# STM32H743 register map
File version: 2.4
CPU: CM7 r0p1, little endian, MPU, FPU, 4 interrupt priority bits
Registers are 32-bit, read-write, reset 0x0 unless marked. A register's access mark holds for its fields unless they carry their own. Offsets are from the block's base; [hi:lo] are bit positions; {n}, {i} and the like mark numbered series; 'fields as' and 'values as' point back to an identical list.

## RAMECC2 — ECC 控制器与各 RAM 区域相关联
Base 0x48023000
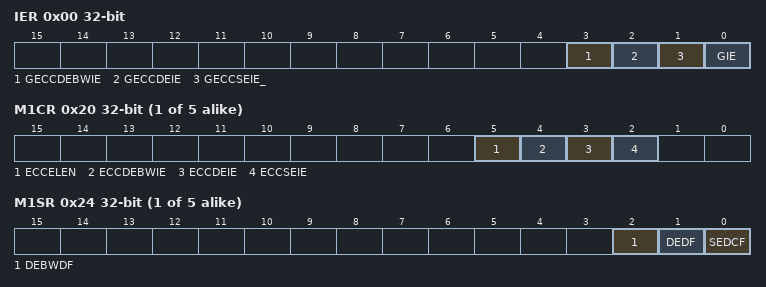
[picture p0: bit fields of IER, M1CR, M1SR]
0x00 IER — RAMECC 中断使能寄存器
  [3] GECCDEBWIE — 全局 ECC 字节写入（BW）双错误中断使能
  [2] GECCDEIE — 全局 ECC 双错误中断使能
  [1] GECCSEIE_ — 全局 ECC 单错误中断使能
  [0] GIE — 全局中断使能
{0x0+0x20*i} M{i}CR (i=1..5) — RAMECC 监视器 x 配置寄存器
  [5] ECCELEN — ECC 错误锁存使能
  [4] ECCDEBWIE — ECC 字节写入（BW）双错误中断使能
  [3] ECCDEIE — ECC 双错误中断使能
  [2] ECCSEIE — ECC 单错误中断使能
{0x4+0x20*i} M{i}SR (i=1..5) — RAMECC 监视器 x 状态寄存器
  [2] DEBWDF — ECC 字节写入（BW）双错误检测标志
  [1] DEDF — ECC 双错误检测标志
  [0] SEDCF — ECC 单错误检测并纠正标志
{0x8+0x20*i} M{i}FAR ro (i=1..4) — RAMECC 监视器 x 故障地址寄存器
  [31:0] FADD — ECC 错误故障地址
{0xC+0x20*i} M{i}FDRL ro (i=1..5) — RAMECC 监视器 x 故障数据低字寄存器
  [31:0] FDATAL — 故障数据低字
0x30 M1FDRH ro — RAMECC 监视器 x 故障数据高字寄存器
  [31:0] FDATAH — 故障数据高字（64 位存储器）
0x34 M1FECR — RAMECC 监视器 x 故障 ECC 错误码寄存器
  [31:0] FEC — 故障错误码
0x50 M2FDRH — RAMECC 监视器 x 故障数据高字寄存器
  [31:0] FDATAH — 故障数据高字（64 位存储器）
0x58 M2FECR — RAMECC 监视器 x 故障 ECC 错误码寄存器
  [31:0] FEC — 故障错误码
0x70 M3FDRH ro — RAMECC 监视器 x 故障数据高字寄存器
  [31:0] FDATAH — 故障数据高字（64 位存储器）
0x7C M3FECR ro — RAMECC 监视器 x 故障 ECC 错误码寄存器
  [31:0] FEC — 故障错误码
0x90 M4FDRH ro — RAMECC 监视器 x 故障数据高字寄存器
  [31:0] FDATAH — 故障数据高字（64 位存储器）
0x90 M4FECR ro (alternate view of M4FDRH) — RAMECC 监视器 x 故障 ECC 错误码寄存器
  [31:0] FEC — 故障错误码
0xA8 M5FAR — RAMECC 监视器 x 故障地址寄存器
  [31:0] FADD — ECC 错误故障地址
0xB0 M5FDRH ro — RAMECC 监视器 x 故障数据高字寄存器
  [31:0] FEC — 故障错误码
0xB4 M5FECR ro — RAMECC 监视器 x 故障 ECC 错误码寄存器
  [31:0] FEC — 故障错误码

## RAMECC3 — ECC 控制器与各 RAM 区域相关联
Base 0x58027000
Registers as RAMECC2, without M{n}CR (n=3..5), M{n}SR (n=3..5), M{n}FAR (n=3..5), M{n}FDRL (n=3..5), M{n}FDRH (n=3..5), M{n}FECR (n=3..5).

## DELAY_Block_SDMMC1 — SDMMC1 延时模块
Base 0x52008000
Same registers: DELAY_Block_SDMMC2 0x48022800, DELAY_Block_QUADSPI 0x52006000
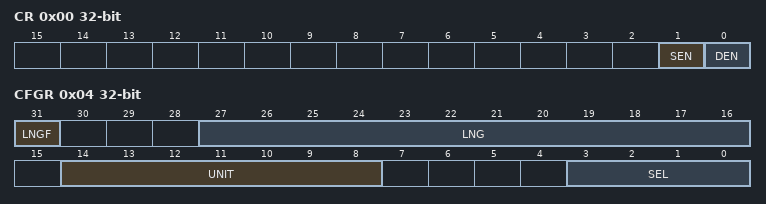
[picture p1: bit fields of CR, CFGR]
0x00 CR — DLYB 控制寄存器
  [1] SEN — 采样长度使能位
  [0] DEN — 延时模块使能位
0x04 CFGR — DLYB 配置寄存器
  [31] LNGF — 长度有效标志
  [27:16] LNG — 延时线长度值
  [14:8] UNIT — 定义单位延时单元的延时量
  [3:0] SEL — 选择输出时钟的相位

## AXI — AXI 互连寄存器
Base 0x51000000
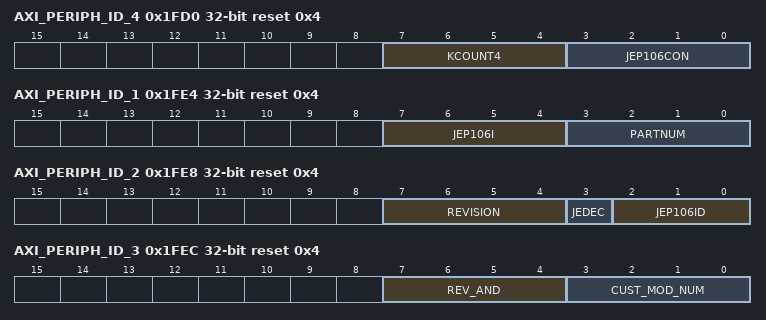
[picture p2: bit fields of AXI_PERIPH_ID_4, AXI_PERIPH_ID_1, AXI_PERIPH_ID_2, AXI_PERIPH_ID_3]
0x1FD0 AXI_PERIPH_ID_4 ro reset 0x4 — AXI 互连 - 外设 ID4 寄存器
  [7:4] KCOUNT4 — 寄存器文件大小
  [3:0] JEP106CON — JEP106 延续码
0x1FE0 AXI_PERIPH_ID_0 ro reset 0x4 — AXI 互连 - 外设 ID0 寄存器
  [7:0] PARTNUM — 外设部件编号位 0~7
0x1FE4 AXI_PERIPH_ID_1 ro reset 0x4 — AXI 互连 - 外设 ID1 寄存器
  [7:4] JEP106I — JEP106 标识位 0~3
  [3:0] PARTNUM — 外设部件编号位 8~11
0x1FE8 AXI_PERIPH_ID_2 ro reset 0x4 — AXI 互连 - 外设 ID2 寄存器
  [7:4] REVISION — 外设版本号
  [3] JEDEC — JEP106 编码标志
  [2:0] JEP106ID — JEP106 标识位 4~6
0x1FEC AXI_PERIPH_ID_3 ro reset 0x4 — AXI 互连 - 外设 ID3 寄存器
  [7:4] REV_AND — 客户版本
  [3:0] CUST_MOD_NUM — 客户修改
0x1FF0 AXI_COMP_ID_0 ro reset 0x4 — AXI 互连 - 组件 ID0 寄存器
  [7:0] PREAMBLE — 前导码位 0~7
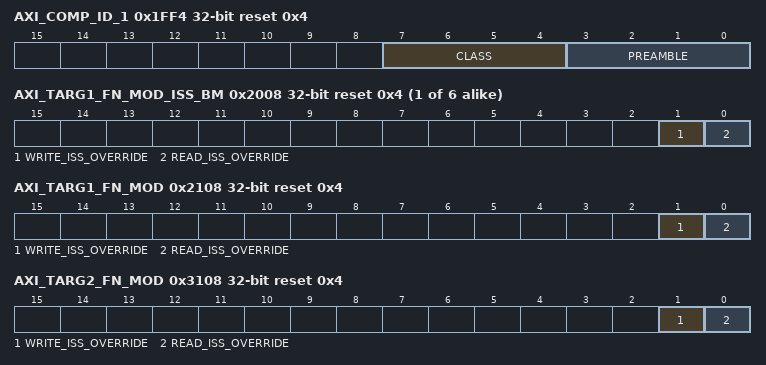
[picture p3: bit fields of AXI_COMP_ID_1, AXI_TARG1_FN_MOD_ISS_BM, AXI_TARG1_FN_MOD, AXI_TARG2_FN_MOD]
0x1FF4 AXI_COMP_ID_1 ro reset 0x4 — AXI 互连 - 组件 ID1 寄存器
  [7:4] CLASS — 组件类别
  [3:0] PREAMBLE — 前导码位 8~11
0x1FF8 AXI_COMP_ID_2 ro reset 0x4 — AXI 互连 - 组件 ID2 寄存器
  [7:0] PREAMBLE — 前导码位 12~19
0x1FFC AXI_COMP_ID_3 ro reset 0x4 — AXI 互连 - 组件 ID3 寄存器
  [7:0] PREAMBLE — 前导码位 20~27
{0x1008+0x1000*i} AXI_TARG{i}_FN_MOD_ISS_BM reset 0x4 (i=1..6) — AXI 互连 - TARG x 总线矩阵发送功能寄存器
  [1] WRITE_ISS_OVERRIDE — 目标端交换矩阵写发送覆写
  [0] READ_ISS_OVERRIDE — 读发送覆写
0x2024 AXI_TARG1_FN_MOD2 reset 0x4 — AXI 互连 - TARG x 总线矩阵功能 2 寄存器
  [0] BYPASS_MERGE — 禁用节拍合并以匹配输出数据位宽
0x202C AXI_TARG1_FN_MOD_LB reset 0x4 — AXI 互连 - TARG x 长突发功能修改寄存器
  [0] FN_MOD_LB — 控制长突发的突发拆分
0x2108 AXI_TARG1_FN_MOD reset 0x4 — AXI 互连 - TARG x 长突发功能修改寄存器
  [1] WRITE_ISS_OVERRIDE — 覆写 AMIB 写发送能力
  [0] READ_ISS_OVERRIDE — 覆写 AMIB 读发送能力
0x3024 AXI_TARG2_FN_MOD2 reset 0x4 — AXI 互连 - TARG x 总线矩阵功能 2 寄存器
  [0] BYPASS_MERGE — 禁用节拍合并以匹配输出数据位宽
0x302C AXI_TARG2_FN_MOD_LB reset 0x4 — AXI 互连 - TARG x 长突发功能修改寄存器
  [0] FN_MOD_LB — 控制长突发的突发拆分
0x3108 AXI_TARG2_FN_MOD reset 0x4 — AXI 互连 - TARG x 长突发功能修改寄存器
  fields as AXI_TARG1_FN_MOD
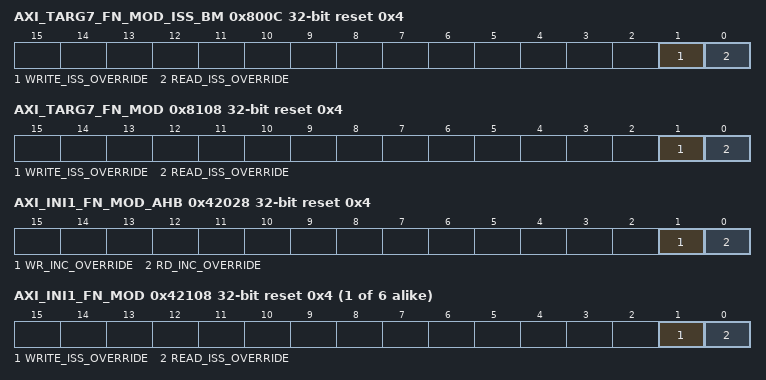
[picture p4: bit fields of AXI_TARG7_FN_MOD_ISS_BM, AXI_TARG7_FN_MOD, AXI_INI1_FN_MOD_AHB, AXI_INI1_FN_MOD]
0x800C AXI_TARG7_FN_MOD_ISS_BM reset 0x4 — AXI 互连 - TARG x 总线矩阵发送功能寄存器
  fields as AXI_TARG1_FN_MOD_ISS_BM
0x8024 AXI_TARG7_FN_MOD2 reset 0x4 — AXI 互连 - TARG x 总线矩阵功能 2 寄存器
  [0] BYPASS_MERGE — 禁用节拍合并以匹配输出数据位宽
0x8108 AXI_TARG7_FN_MOD reset 0x4 — AXI 互连 - TARG x 长突发功能修改寄存器
  fields as AXI_TARG1_FN_MOD
0x42024 AXI_INI1_FN_MOD2 reset 0x4 — AXI 互连 - INI x 功能修改 2 寄存器
  [0] BYPASS_MERGE — 禁止上行位宽转换器修改传输事务（协议要求时除外）
0x42028 AXI_INI1_FN_MOD_AHB reset 0x4 — AXI 互连 - INI x AHB 功能修改寄存器
  [1] WR_INC_OVERRIDE — 将所有 AHB-Lite 读传输转换为一系列单节拍 AXI 传输
  [0] RD_INC_OVERRIDE — 将所有 AHB-Lite 写传输转换为一系列单节拍 AXI 传输
{0x41100+0x1000*i} AXI_INI{i}_READ_QOS reset 0x4 (i=1..6) — AXI 互连 - INI x 读 QoS 寄存器
  [3:0] AR_QOS — 读通道 QoS 设置
{0x41104+0x1000*i} AXI_INI{i}_WRITE_QOS reset 0x4 (i=1..6) — AXI 互连 - INI x 写 QoS 寄存器
  [3:0] AW_QOS — 写通道 QoS 设置
{0x41108+0x1000*i} AXI_INI{i}_FN_MOD reset 0x4 (i=1..6) — AXI 互连 - INI x 发送功能修改寄存器
  [1] WRITE_ISS_OVERRIDE — 覆写 ASIB 写发送能力
  [0] READ_ISS_OVERRIDE — 覆写 ASIB 读发送能力
0x44024 AXI_INI3_FN_MOD2 reset 0x4 — AXI 互连 - INI x 功能修改 2 寄存器
  [0] BYPASS_MERGE — 禁止上行位宽转换器修改传输事务（协议要求时除外）
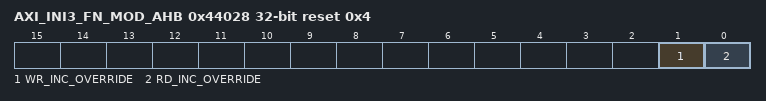
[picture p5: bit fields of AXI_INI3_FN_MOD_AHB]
0x44028 AXI_INI3_FN_MOD_AHB reset 0x4 — AXI 互连 - INI x AHB 功能修改寄存器
  fields as AXI_INI1_FN_MOD_AHB
